# RF13M_Module_1 register map
Vendor: Texas Instruments
Peripheral module from a debugger description file (folder msp430).
Registers are 16-bit, access not given, no defined reset value unless marked. A register's access mark holds for its fields unless they carry their own. Offsets are as the file gives them; lines under a group give offsets from that group; [hi:lo] are bit positions; {n}, {i} and the like mark numbered series; 'fields as' and 'values as' point back to an identical list; <NAME> marks a mode.

## RF13M_Module
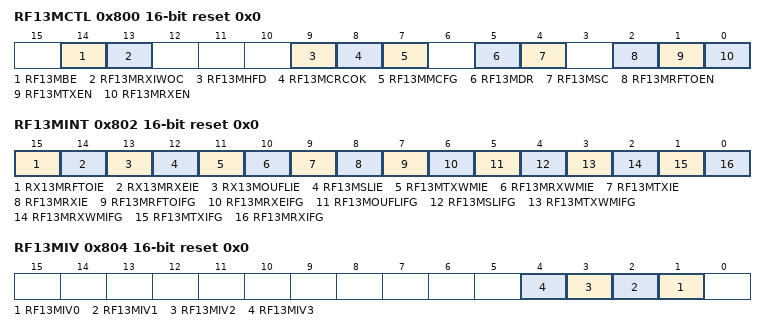
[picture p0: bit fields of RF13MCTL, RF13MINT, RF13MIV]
0x800 RF13MCTL rw reset 0x0 — RF13M Control register
  [14] RF13MBE — RF13M Select between big or little endian mode
  [13] RF13MRXIWOC — RF13M Gate RX interrupt with CRC OK
  [9] RF13MHFD — RF13M Indicates if a HF field was detected since last readout
  [8] RF13MCRCOK — RF13M CRC valued correct or not flag
  [7] RF13MMCFG — RF13M Enable manual configuration of ISO15693 uplink parameters
  [5] RF13MDR — RF13M Manually select uplink data rate
  [4] RF13MSC — RF13M Manually select uplink subcarrier setting
  [2] RF13MRFTOEN — RF13M Enable RF Field timeout detection
  [1] RF13MTXEN — RF13M Enable transmission of uplink
  [0] RF13MRXEN — RF13M Enable reception of downlink
0x802 RF13MINT rw reset 0x0 — RF13M Interrupt Enable/Flag register
  [15] RX13MRFTOIE — RF13M RF Timeout detected interrupt enable
  [14] RX13MRXEIE — RF13M RX Error interrupt enable
  [13] RX13MOUFLIE — RF13M Over-/Under-flow interrupt enable
  [12] RF13MSLIE — RF13M ISO15693 Slot marker interrupt enable
  [11] RF13MTXWMIE — RF13M TX FIFO low watermark interrupt enable
  [10] RF13MRXWMIE — RF13M RX FIFO high watermark interrupt enable
  [9] RF13MTXIE — RF13M TX done interrupt enable
  [8] RF13MRXIE — RF13M RX done interrupt enable
  [7] RF13MRFTOIFG — RF13M RF Timeout detected
  [6] RF13MRXEIFG — RF13M RX Error detected
  [5] RF13MOUFLIFG — RF13M Over-/Under-flow condition detected
  [4] RF13MSLIFG — RF13M RX Slot marker interrupt flag
  [3] RF13MTXWMIFG — RF13M TX FIFO low watermark reached interrupt flag
  [2] RF13MRXWMIFG — RF13M RX FIFO high watermark reached interrupt flag
  [1] RF13MTXIFG — RF13M Uplink transmission done interrupt flag
  [0] RF13MRXIFG — RF13M Receive downlink done interrupt flag
0x804 RF13MIV rw reset 0x0 — RF13M Interrupt Vector register
  [n+1] RF13MIV{n} (n=0..3) — RF13M Interrupt vector value bit: {n}
0x806 RF13MRXF — RF13M Receive Data FIFO register
0x808 RF13MTXF — RF13M Transmit Data FIFO register
0x80A RF13MCRC — RF13M CRC accumulator register
0x80C RF13MFIFOFL — RF13M Receive/Transmit Data FIFO Fill Level register
0x80E RF13MWMCFG — RF13M Receive High/Transmit Low Watermark configuration register
0x820 RF13MRXBUF — RF13M Receive data buffer
0x840 RF13MTXBUF — RF13M Transmit data buffer
